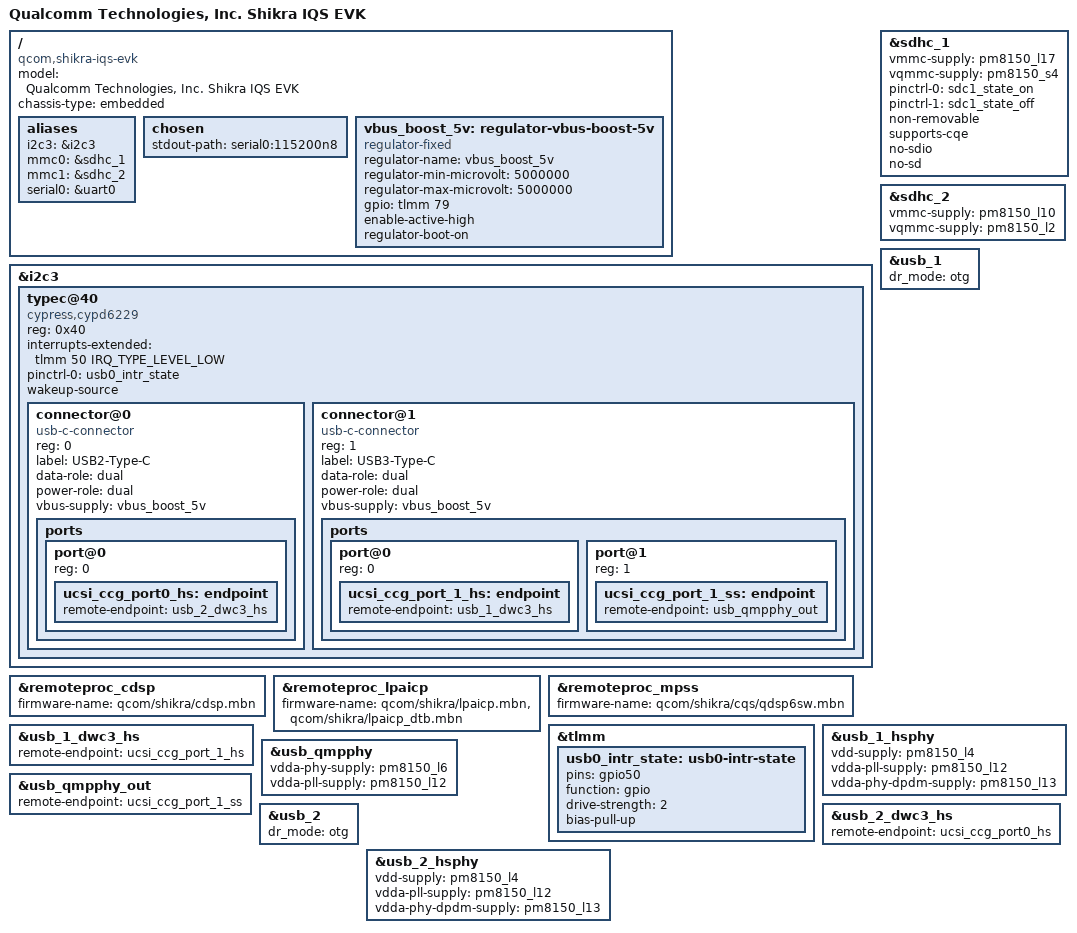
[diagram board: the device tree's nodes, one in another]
// SPDX-License-Identifier: BSD-3-Clause
/*
 * Copyright (c) Qualcomm Technologies, Inc. and/or its subsidiaries.
 */

/dts-v1/;

#include "shikra-iqs-som.dtsi"
#include "shikra-evk.dtsi"
#include <dt-bindings/gpio/gpio.h>

/ {
	model = "Qualcomm Technologies, Inc. Shikra IQS EVK";
	compatible = "qcom,shikra-iqs-evk", "qcom,shikra-iqs-som", "qcom,shikra";
	chassis-type = "embedded";

	aliases {
		i2c3 = &i2c3;
		mmc0 = &sdhc_1;
		mmc1 = &sdhc_2; /* SDC2 SD card slot */
		serial0 = &uart0;
	};

	chosen {
		stdout-path = "serial0:115200n8";
	};

	vbus_boost_5v: regulator-vbus-boost-5v {
		compatible = "regulator-fixed";
		regulator-name = "vbus_boost_5v";
		regulator-min-microvolt = <5000000>;
		regulator-max-microvolt = <5000000>;
		gpio = <&tlmm 79 GPIO_ACTIVE_HIGH>;
		enable-active-high;
		regulator-boot-on;
	};
};

&i2c3 {
	status = "okay";

	typec@40 {
		compatible = "cypress,cypd6229", "cypress,cypd6129";
		reg = <0x40>;
		interrupts-extended = <&tlmm 50 IRQ_TYPE_LEVEL_LOW>;
		pinctrl-0 = <&usb0_intr_state>;
		pinctrl-names = "default";
		wakeup-source;

		#address-cells = <1>;
		#size-cells = <0>;

		connector@0 {
			compatible = "usb-c-connector";
			reg = <0>;
			label = "USB2-Type-C";
			data-role = "dual";
			power-role = "dual";
			vbus-supply = <&vbus_boost_5v>;

			ports {
				#address-cells = <1>;
				#size-cells = <0>;

				port@0 {
					reg = <0>;

					ucsi_ccg_port0_hs: endpoint {
						remote-endpoint = <&usb_2_dwc3_hs>;
					};
				};
			};
		};

		connector@1 {
			compatible = "usb-c-connector";
			reg = <1>;
			label = "USB3-Type-C";
			data-role = "dual";
			power-role = "dual";
			vbus-supply = <&vbus_boost_5v>;

			ports {
				#address-cells = <1>;
				#size-cells = <0>;

				port@0 {
					reg = <0>;

					ucsi_ccg_port_1_hs: endpoint {
						remote-endpoint = <&usb_1_dwc3_hs>;
					};
				};

				port@1 {
					reg = <1>;

					ucsi_ccg_port_1_ss: endpoint {
						remote-endpoint = <&usb_qmpphy_out>;
					};
				};
			};
		};
	};
};

&remoteproc_cdsp {
	firmware-name = "qcom/shikra/cdsp.mbn";

	status = "okay";
};

&remoteproc_lpaicp {
	firmware-name = "qcom/shikra/lpaicp.mbn",
			"qcom/shikra/lpaicp_dtb.mbn";

	status = "okay";
};

&remoteproc_mpss {
	firmware-name = "qcom/shikra/cqs/qdsp6sw.mbn";

	status = "okay";
};

&sdhc_1 {
	vmmc-supply = <&pm8150_l17>;
	vqmmc-supply = <&pm8150_s4>;

	pinctrl-0 = <&sdc1_state_on>;
	pinctrl-1 = <&sdc1_state_off>;
	pinctrl-names = "default", "sleep";

	non-removable;
	supports-cqe;
	no-sdio;
	no-sd;

	status = "okay";
};

&sdhc_2 {
	vmmc-supply = <&pm8150_l10>;
	vqmmc-supply = <&pm8150_l2>;

	status = "okay";
};

&tlmm {
	usb0_intr_state: usb0-intr-state {
		pins = "gpio50";
		function = "gpio";
		drive-strength = <2>;
		bias-pull-up;
	};
};

&usb_1 {
	dr_mode = "otg";
};

&usb_1_dwc3_hs {
	remote-endpoint = <&ucsi_ccg_port_1_hs>;
};

&usb_1_hsphy {
	vdd-supply = <&pm8150_l4>;
	vdda-pll-supply = <&pm8150_l12>;
	vdda-phy-dpdm-supply = <&pm8150_l13>;

	status = "okay";
};

&usb_qmpphy {
	vdda-phy-supply = <&pm8150_l6>;
	vdda-pll-supply = <&pm8150_l12>;

	status = "okay";
};

&usb_qmpphy_out {
	remote-endpoint = <&ucsi_ccg_port_1_ss>;
};

&usb_2 {
	dr_mode = "otg";
};

&usb_2_dwc3_hs {
	remote-endpoint = <&ucsi_ccg_port0_hs>;
};

&usb_2_hsphy {
	vdd-supply = <&pm8150_l4>;
	vdda-pll-supply = <&pm8150_l12>;
	vdda-phy-dpdm-supply = <&pm8150_l13>;

	status = "okay";
};
